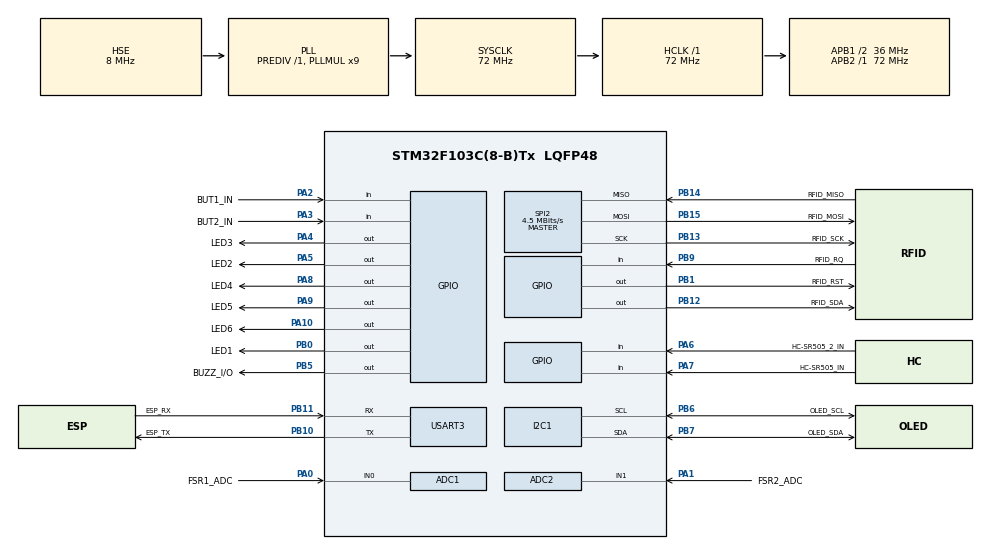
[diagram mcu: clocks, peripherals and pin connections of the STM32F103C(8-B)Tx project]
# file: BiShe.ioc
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ADC1.Channel-0\#ChannelRegularConversion=ADC_CHANNEL_0
ADC1.NbrOfConversion=1
ADC1.NbrOfConversionFlag=1
ADC1.Rank-0\#ChannelRegularConversion=1
ADC1.SamplingTime-0\#ChannelRegularConversion=ADC_SAMPLETIME_239CYCLES_5
ADC1.master=1
ADC2.Channel-0\#ChannelRegularConversion=ADC_CHANNEL_1
ADC2.NbrOfConversion=1
ADC2.NbrOfConversionFlag=1
ADC2.Rank-0\#ChannelRegularConversion=1
ADC2.SamplingTime-0\#ChannelRegularConversion=ADC_SAMPLETIME_239CYCLES_5
Mcu.Family=STM32F1
Mcu.Name=STM32F103C(8-B)Tx
Mcu.Package=LQFP48
NVIC.PriorityGroup=NVIC_PRIORITYGROUP_4
PA0-WKUP.GPIO_Label=FSR1_ADC
PA0-WKUP.Signal=SharedAnalog_PA0
PA13.Mode=Serial_Wire
PA13.Signal=SYS_JTMS-SWDIO
PA14.Mode=Serial_Wire
PA14.Signal=SYS_JTCK-SWCLK
PA1.GPIO_Label=FSR2_ADC
PA1.Signal=SharedAnalog_PA1
PA2.GPIO_Label=BUT1_IN
PA2.GPIO_PuPd=GPIO_PULLUP
PA2.Signal=GPIO_Input
PA3.GPIO_Label=BUT2_IN
PA3.GPIO_PuPd=GPIO_PULLUP
PA3.Signal=GPIO_Input
PA4.GPIO_Label=LED3
PA4.Signal=GPIO_Output
PA5.GPIO_Label=LED2
PA5.Signal=GPIO_Output
PA6.GPIO_Label=HC-SR505_2_IN
PA6.GPIO_PuPd=GPIO_PULLDOWN
PA6.Signal=GPIO_Input
PA7.GPIO_Label=HC-SR505_IN
PA7.GPIO_PuPd=GPIO_PULLDOWN
PA7.Signal=GPIO_Input
PA8.GPIO_Label=LED4
PA8.Signal=GPIO_Output
PA9.GPIO_Label=LED5
PA9.Signal=GPIO_Output
PA10.GPIO_Label=LED6
PA10.Signal=GPIO_Output
PB0.GPIO_Label=LED1
PB0.Signal=GPIO_Output
PB1.GPIO_Label=RFID_RST
PB1.Signal=GPIO_Output
PB10.GPIO_Label=ESP_TX
PB10.Mode=Asynchronous
PB10.Signal=USART3_TX
PB11.GPIO_Label=ESP_RX
PB11.Mode=Asynchronous
PB11.Signal=USART3_RX
PB12.GPIO_Label=RFID_SDA
PB12.PinState=GPIO_PIN_SET
PB12.Signal=GPIO_Output
PB13.GPIO_Label=RFID_SCK
PB13.Mode=Full_Duplex_Master
PB13.Signal=SPI2_SCK
PB14.GPIO_Label=RFID_MISO
PB14.Mode=Full_Duplex_Master
PB14.Signal=SPI2_MISO
PB15.GPIO_Label=RFID_MOSI
PB15.Mode=Full_Duplex_Master
PB15.Signal=SPI2_MOSI
PB5.GPIO_Label=BUZZ_I/O
PB5.Signal=GPIO_Output
PB6.GPIO_Label=OLED_SCL
PB6.Mode=I2C
PB6.Signal=I2C1_SCL
PB7.GPIO_Label=OLED_SDA
PB7.Mode=I2C
PB7.Signal=I2C1_SDA
PB9.GPIO_Label=RFID_RQ
PB9.Signal=GPIO_Input
PC14-OSC32_IN.Mode=LSE-External-Oscillator
PC14-OSC32_IN.Signal=RCC_OSC32_IN
PC15-OSC32_OUT.Mode=LSE-External-Oscillator
PC15-OSC32_OUT.Signal=RCC_OSC32_OUT
PD0-OSC_IN.Mode=HSE-External-Oscillator
PD0-OSC_IN.Signal=RCC_OSC_IN
PD1-OSC_OUT.Mode=HSE-External-Oscillator
PD1-OSC_OUT.Signal=RCC_OSC_OUT
ProjectManager.HeapSize=0x200
ProjectManager.StackSize=0x800
ProjectManager.TargetToolchain=STM32CubeIDE
RCC.ADCPresc=RCC_ADCPCLK2_DIV6
RCC.AHBFreq_Value=72000000
RCC.APB1CLKDivider=RCC_HCLK_DIV2
RCC.APB1Freq_Value=36000000
RCC.APB1TimFreq_Value=72000000
RCC.APB2Freq_Value=72000000
RCC.APB2TimFreq_Value=72000000
RCC.HCLKFreq_Value=72000000
RCC.PLLMUL=RCC_PLL_MUL9
RCC.PLLSourceVirtual=RCC_PLLSOURCE_HSE
RCC.SYSCLKFreq_VALUE=72000000
RCC.SYSCLKSource=RCC_SYSCLKSOURCE_PLLCLK
RCC.USBFreq_Value=72000000
SH.SharedAnalog_PA0.0=GPIO_Analog
SH.SharedAnalog_PA0.1=ADC1_IN0,IN0
SH.SharedAnalog_PA1.0=GPIO_Analog
SH.SharedAnalog_PA1.1=ADC2_IN1,IN1
SPI2.BaudRatePrescaler=SPI_BAUDRATEPRESCALER_8
SPI2.CalculateBaudRate=4.5 MBits/s
SPI2.Direction=SPI_DIRECTION_2LINES
SPI2.Mode=SPI_MODE_MASTER
SPI2.VirtualType=VM_MASTER
USART3.VirtualMode=VM_ASYNC
board=custom

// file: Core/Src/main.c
/* USER CODE BEGIN Header */
/**
  ******************************************************************************
  * @file           : main.c
  * @brief          : Main program body
  ******************************************************************************
  * @attention
  *
  * Copyright (c) 2026 STMicroelectronics.
  * All rights reserved.
  *
  * This software is licensed under terms that can be found in the LICENSE file
  * in the root directory of this software component.
  * If no LICENSE file comes with this software, it is provided AS-IS.
  *
  ******************************************************************************
  */
/* USER CODE END Header */
#include "main.h"
#include "adc.h"
#include "i2c.h"
#include "spi.h"
#include "usart.h"
#include "gpio.h"

/* USER CODE BEGIN Includes */
#include "app_config.h"   /* device identity / topics / timing / thresholds (pin macros live in main.h) */
#include "seat_app.h"     /* seat terminal app: inits FSR/OLED/RFID/ESP8266/buzzer internally */
/* USER CODE END Includes */

void SystemClock_Config(void);

int main(void)
{

  /* MCU Configuration--------------------------------------------------------*/

  /* Reset of all peripherals, Initializes the Flash interface and the Systick. */
  HAL_Init();

  /* Configure the system clock */
  SystemClock_Config();

  /* Initialize all configured peripherals */
  MX_GPIO_Init();
  MX_ADC1_Init();
  MX_ADC2_Init();
  MX_I2C1_Init();
  MX_SPI2_Init();
  MX_USART3_UART_Init();
  /* USER CODE BEGIN 2 */
  /* Init seat terminal: FSR capture (with ADC self-calibration on F1), OLED, RFID, ESP8266, buzzer;
     whether it auto-connects on boot is controlled by APP_AUTOSTART_CONNECT in app_config.h. */
  SEAT_App_Init();
  /* USER CODE END 2 */

  /* Infinite loop */
  /* USER CODE BEGIN WHILE */
  while (1)
  {
    /* Capture / dual-sensor fusion / OLED / card swipe / buzzer;
       in online mode it also runs the connection state machine, keep-alive and downlink dispatch. */
    SEAT_App_Process();

    /* USER CODE END WHILE */

  }
}

void SystemClock_Config(void)
{
  RCC_OscInitTypeDef RCC_OscInitStruct = {0};
  RCC_ClkInitTypeDef RCC_ClkInitStruct = {0};
  RCC_PeriphCLKInitTypeDef PeriphClkInit = {0};

  /** Initializes the RCC Oscillators according to the specified parameters
  * in the RCC_OscInitTypeDef structure.
  */
  RCC_OscInitStruct.OscillatorType = RCC_OSCILLATORTYPE_HSE;
  RCC_OscInitStruct.HSEState = RCC_HSE_ON;
  RCC_OscInitStruct.HSEPredivValue = RCC_HSE_PREDIV_DIV1;
  RCC_OscInitStruct.HSIState = RCC_HSI_ON;
  RCC_OscInitStruct.PLL.PLLState = RCC_PLL_ON;
  RCC_OscInitStruct.PLL.PLLSource = RCC_PLLSOURCE_HSE;
  RCC_OscInitStruct.PLL.PLLMUL = RCC_PLL_MUL9;
  if (HAL_RCC_OscConfig(&RCC_OscInitStruct) != HAL_OK)
  {
    Error_Handler();
  }
  /** Initializes the CPU, AHB and APB buses clocks
  */
  RCC_ClkInitStruct.ClockType = RCC_CLOCKTYPE_HCLK|RCC_CLOCKTYPE_SYSCLK
                              |RCC_CLOCKTYPE_PCLK1|RCC_CLOCKTYPE_PCLK2;
  RCC_ClkInitStruct.SYSCLKSource = RCC_SYSCLKSOURCE_PLLCLK;
  RCC_ClkInitStruct.AHBCLKDivider = RCC_SYSCLK_DIV1;
  RCC_ClkInitStruct.APB1CLKDivider = RCC_HCLK_DIV2;
  RCC_ClkInitStruct.APB2CLKDivider = RCC_HCLK_DIV1;

  if (HAL_RCC_ClockConfig(&RCC_ClkInitStruct, FLASH_LATENCY_2) != HAL_OK)
  {
    Error_Handler();
  }
  PeriphClkInit.PeriphClockSelection = RCC_PERIPHCLK_ADC;
  PeriphClkInit.AdcClockSelection = RCC_ADCPCLK2_DIV6;
  if (HAL_RCCEx_PeriphCLKConfig(&PeriphClkInit) != HAL_OK)
  {
    Error_Handler();
  }
}

void Error_Handler(void)
{
  __disable_irq();
  while (1)
  {
  }
}
